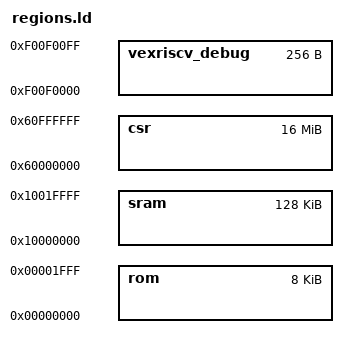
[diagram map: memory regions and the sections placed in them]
MEMORY {
	csr : ORIGIN = 0x60000000, LENGTH = 0x01000000
	vexriscv_debug : ORIGIN = 0xf00f0000, LENGTH = 0x00000100
	sram : ORIGIN = 0x10000000, LENGTH = 0x00020000
	rom : ORIGIN = 0x00000000, LENGTH = 0x00002000
}
